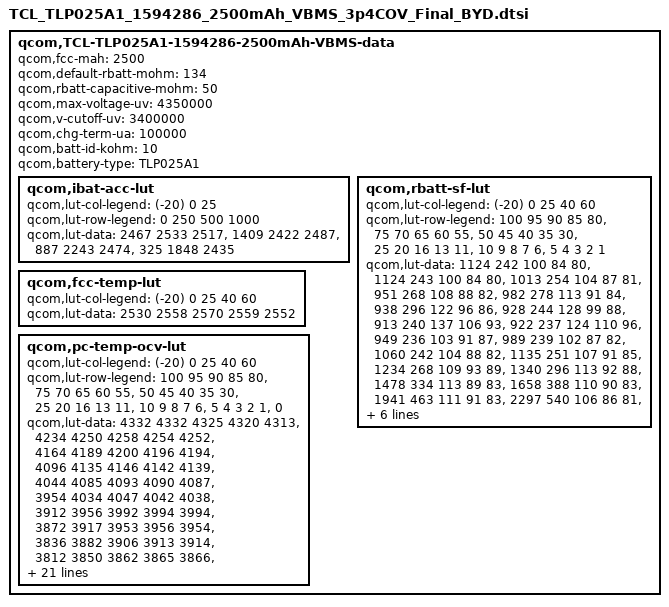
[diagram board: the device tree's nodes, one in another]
 qcom,TCL-TLP025A1-1594286-2500mAh-VBMS-data {
	qcom,fcc-mah = <2500>;
	qcom,default-rbatt-mohm = <134>;
	qcom,rbatt-capacitive-mohm = <50>;
	qcom,max-voltage-uv = <4350000>;
	qcom,v-cutoff-uv = <3400000>;
	qcom,chg-term-ua = <100000>;
	qcom,batt-id-kohm = <10>;
	qcom,battery-type = "TLP025A1";

	qcom,ibat-acc-lut {
		qcom,lut-col-legend = <(-20) 0 25>;
		qcom,lut-row-legend = <0 250 500 1000>;
		qcom,lut-data = <2467 2533 2517>,
				<1409 2422 2487>,
				<887 2243 2474>,
				<325 1848 2435>;
	};

	qcom,rbatt-sf-lut {
		qcom,lut-col-legend = <(-20) 0 25 40 60>;
		qcom,lut-row-legend = <100 95 90 85 80>,
				<75 70 65 60 55>,
				<50 45 40 35 30>,
				<25 20 16 13 11>,
				<10 9 8 7 6>,
				<5 4 3 2 1>;
		qcom,lut-data = <1124 242 100 84 80>,
				<1124 243 100 84 80>,
				<1013 254 104 87 81>,
				<951 268 108 88 82>,
				<982 278 113 91 84>,
				<938 296 122 96 86>,
				<928 244 128 99 88>,
				<913 240 137 106 93>,
				<922 237 124 110 96>,
				<949 236 103 91 87>,
				<989 239 102 87 82>,
				<1060 242 104 88 82>,
				<1135 251 107 91 85>,
				<1234 268 109 93 89>,
				<1340 296 113 92 88>,
				<1478 334 113 89 83>,
				<1658 388 110 90 83>,
				<1941 463 111 91 83>,
				<2297 540 106 86 81>,
				<2175 562 109 88 84>,
				<2367 601 113 90 84>,
				<2613 639 118 93 86>,
				<2907 682 125 96 88>,
				<3251 734 131 97 91>,
				<3711 796 134 99 92>,
				<4321 849 130 96 85>,
				<5401 928 134 95 86>,
				<6628 1010 145 99 89>,
				<9115 1118 167 107 98>,
				<24693 1434 4933 159 143>;
	};

	qcom,fcc-temp-lut {
		qcom,lut-col-legend = <(-20) 0 25 40 60>;
		qcom,lut-data = <2530 2558 2570 2559 2552>;
	};

	qcom,pc-temp-ocv-lut {
		qcom,lut-col-legend = <(-20) 0 25 40 60>;
		qcom,lut-row-legend = <100 95 90 85 80>,
				<75 70 65 60 55>,
				<50 45 40 35 30>,
				<25 20 16 13 11>,
				<10 9 8 7 6>,
				<5 4 3 2 1>,
				<0>;
		qcom,lut-data = <4332 4332 4325 4320 4313>,
				<4234 4250 4258 4254 4252>,
				<4164 4189 4200 4196 4194>,
				<4096 4135 4146 4142 4139>,
				<4044 4085 4093 4090 4087>,
				<3954 4034 4047 4042 4038>,
				<3912 3956 3992 3994 3994>,
				<3872 3917 3953 3956 3954>,
				<3836 3882 3906 3913 3914>,
				<3812 3850 3862 3865 3866>,
				<3795 3823 3834 3834 3834>,
				<3780 3800 3812 3812 3811>,
				<3767 3783 3794 3794 3793>,
				<3754 3772 3780 3779 3778>,
				<3741 3761 3768 3765 3760>,
				<3726 3744 3756 3750 3736>,
				<3710 3720 3734 3730 3715>,
				<3692 3704 3706 3705 3690>,
				<3674 3695 3688 3681 3670>,
				<3658 3690 3684 3678 3667>,
				<3647 3686 3683 3678 3666>,
				<3634 3683 3681 3676 3665>,
				<3618 3678 3679 3675 3664>,
				<3599 3672 3675 3672 3660>,
				<3577 3660 3664 3664 3652>,
				<3546 3636 3631 3640 3622>,
				<3508 3602 3580 3594 3572>,
				<3454 3549 3511 3532 3508>,
				<3370 3476 3417 3446 3423>,
				<3245 3356 3266 3319 3296>,
				<3000 3000 3000 3000 3000>;
	};
};
